VERSION "Chunga"
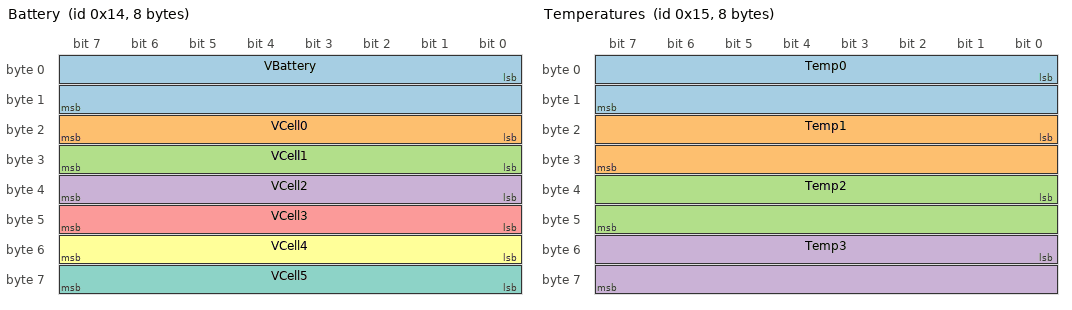
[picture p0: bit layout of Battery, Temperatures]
BO_ 20 Battery: 8 Vector__XXX
	SG_ VBattery : 0|16@1+ (1,0) [1980| 2520] "cvolt #/100#" Vector__XXX
	SG_ VCell0 : 16|8@1+ (1,0) [10| 100] "testing #+320/100#" Vector__XXX
	SG_ VCell1 : 24|8@1+ (1,0) [10| 100] "testing #+320/100#" Vector__XXX
	SG_ VCell2 : 32|8@1+ (1,0) [10| 100] "testing #+320/100#" Vector__XXX
	SG_ VCell3 : 40|8@1+ (1,0) [10| 100] "testing #+320/100#" Vector__XXX
	SG_ VCell4 : 48|8@1+ (1,0) [10| 100] "testing #+320/100#" Vector__XXX
	SG_ VCell5 : 56|8@1+ (1,0) [10| 100] "testing #+320/100#" Vector__XXX

BO_ 21 Temperatures: 8 Vector__XXX
	SG_ Temp0 : 0|16@1+ (1,0) [15| 60] "deg ##" Vector__XXX
	SG_ Temp1 : 16|16@1+ (1,0) [15| 60] "deg ##" Vector__XXX
	SG_ Temp2 : 32|16@1+ (1,0) [15| 60] "deg ##" Vector__XXX
	SG_ Temp3 : 48|16@1+ (1,0) [15| 60] "deg ##" Vector__XXX

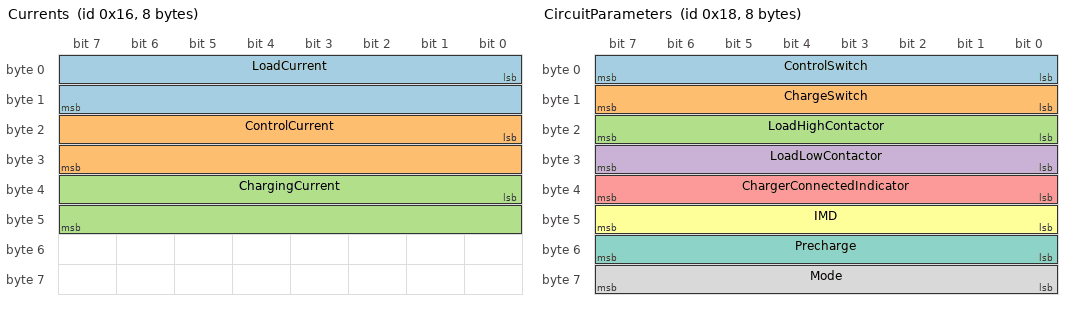
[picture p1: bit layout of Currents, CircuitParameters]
BO_ 22 Currents: 8 Vector__XXX
	SG_ LoadCurrent : 0|16@1+ (1,0) [-1000| 15000] "mamp #/1000#" Vector__XXX
	SG_ ControlCurrent : 16|16@1+ (1,0) [0| 10000] "mamp #/1000#" Vector__XXX
	SG_ ChargingCurrent : 32|16@1+ (1,0) [0| 10000] "mamp #/1000#" Vector__XXX

BO_ 23 SystemVoltage: 8 Vector__XXX
	SG_ TotalSystemVoltage : 0|16@1+ (1,0) [4600| 5000] "cvolt #/100#" Vector__XXX

BO_ 24 CircuitParameters: 8 Vector__XXX
	SG_ ControlSwitch : 0|8@1+ (1,0) [-100| 100] "identity ##" Vector__XXX
	SG_ ChargeSwitch : 8|8@1+ (1,0) [-100| 100] "identity ##" Vector__XXX
	SG_ LoadHighContactor : 16|8@1+ (1,0) [-100| 100] "identity ##" Vector__XXX
	SG_ LoadLowContactor : 24|8@1+ (1,0) [-100| 100] "identity ##" Vector__XXX
	SG_ ChargerConnectedIndicator : 32|8@1+ (1,0) [-100| 100] "identity ##" Vector__XXX
	SG_ IMD : 40|8@1+ (1,0) [-100| 100] "identity ##" Vector__XXX
	SG_ Precharge : 48|8@1+ (1,0) [-100| 100] "identity ##" Vector__XXX
	SG_ Mode : 56|8@1+ (1,0) [-100| 100] "identity ##" Vector__XXX

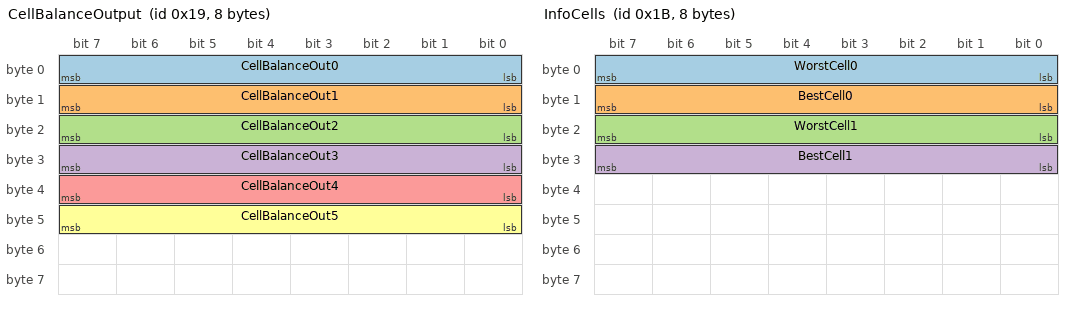
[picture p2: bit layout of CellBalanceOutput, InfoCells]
BO_ 25 CellBalanceOutput: 8 Vector__XXX
	SG_ CellBalanceOut0 : 0|8@1+ (1,0) [-100| 100] "identity ##" Vector__XXX
	SG_ CellBalanceOut1 : 8|8@1+ (1,0) [-100| 100] "identity ##" Vector__XXX
	SG_ CellBalanceOut2 : 16|8@1+ (1,0) [-100| 100] "identity ##" Vector__XXX
	SG_ CellBalanceOut3 : 24|8@1+ (1,0) [-100| 100] "identity ##" Vector__XXX
	SG_ CellBalanceOut4 : 32|8@1+ (1,0) [-100| 100] "identity ##" Vector__XXX
	SG_ CellBalanceOut5 : 40|8@1+ (1,0) [-100| 100] "identity ##" Vector__XXX

BO_ 26 BatteryCapacity: 8 Vector__XXX
	SG_ Capacity0 : 0|16@1+ (1,0) [0| 100] "percent ##" Vector__XXX
	SG_ Capacity1 : 16|16@1+ (1,0) [0| 100] "percent ##" Vector__XXX

BO_ 27 InfoCells: 8 Vector__XXX
	SG_ WorstCell0 : 0|8@1+ (1,0) [10| 100] "testing #+320/100#" Vector__XXX
	SG_ BestCell0 : 8|8@1+ (1,0) [10| 100] "testing #+320/100#" Vector__XXX
	SG_ WorstCell1 : 16|8@1+ (1,0) [10| 100] "testing #+320/100#" Vector__XXX
	SG_ BestCell1 : 24|8@1+ (1,0) [10| 100] "testing #+320/100#" Vector__XXX

BO_ 28 Status: 8 Vector__XXX
	SG_ State : 0|8@1+ (1,0) [-100| 100] "identity ##" Vector__XXX

BO_ 29 ToNormalMode: 8 Vector__XXX

BO_ 30 ToBatteryChargeMode: 8 Vector__XXX

BO_ 31 EmergencyOpenContactor: 8 Vector__XXX

BO_ 32 OpenContactor: 8 Vector__XXX

BO_ 33 CloseContactor: 8 Vector__XXX

BO_ 34 TestContactors: 8 Vector__XXX

BO_ 35 DeactivateProctections: 8 Vector__XXX

BO_ 36 ActivateProctections: 8 Vector__XXX

BO_ 37 TurnOffBoards: 8 Vector__XXX

BO_ 38 TurnOnBoards: 8 Vector__XXX

VERSION "Algo"
BO_ 1 MasterFault: 8 Vector__XXX
	SG_ ProtectionsBitArrayMaster : 0|64@1+ (1,0) [-100| 100] "identity ##" Vector__XXX

BO_ 2 NavBrakesFault: 8 Vector__XXX
	SG_ ProtectionsBitArrayNabBrakes : 0|64@1+ (1,0) [-100| 100] "identity ##" Vector__XXX

BO_ 3 LimFault: 8 Vector__XXX
	SG_ ProtectionsBitArrayLim : 0|64@1+ (1,0) [-100| 100] "identity ##" Vector__XXX

BO_ 4 LCUFault: 8 Vector__XXX
	SG_ ProtectionsBitArrayLCU : 0|64@1+ (1,0) [-100| 100] "identity ##" Vector__XXX

BO_ 5 LPUFault: 8 Vector__XXX
	SG_ ProtectionsBitArrayLPU : 0|64@1+ (1,0) [-100| 100] "identity ##" Vector__XXX

BO_ 6 BMS: 8 Vector__XXX
	SG_ ProtectionsBitArrayBMS : 0|64@1+ (1,0) [-100| 100] "identity ##" Vector__XXX
